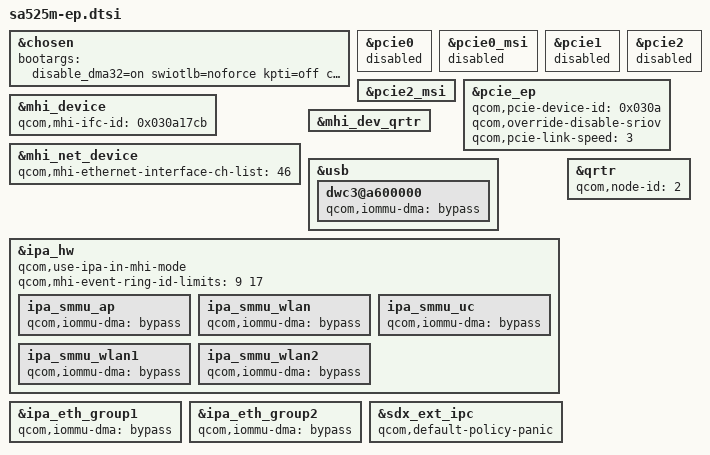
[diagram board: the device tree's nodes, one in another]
&chosen {
	bootargs = "disable_dma32=on swiotlb=noforce kpti=off cpufreq.default_governor=performance pcie_ports=compat msm_rtb.filter=0x237 ftrace_dump_on_oops reboot=w";
};

&pcie0 {
	status = "disabled";
};

&pcie0_msi {
	status = "disabled";
};

&pcie1 {
	status = "disabled";
};

&pcie2 {
	status = "disabled";
};

&pcie2_msi {
	status = "ok";
};

&pcie_ep {
	qcom,pcie-device-id = /bits/ 16 <0x030a>;
	qcom,override-disable-sriov;
	qcom,pcie-link-speed = <3>; /* Set max link speed to Gen3 */
	status = "ok";
};

&mhi_device {
	qcom,mhi-ifc-id = <0x030a17cb>;
	status = "ok";
};

&mhi_net_device {
	qcom,mhi-ethernet-interface-ch-list = <46>;
	status = "ok";
};

&mhi_dev_qrtr {
	status = "ok";
};

&usb {
	dwc3@a600000 {
		qcom,iommu-dma = "bypass";
	};
};
&ipa_hw {
	qcom,use-ipa-in-mhi-mode;
	qcom,mhi-event-ring-id-limits = <9 17>;

	ipa_smmu_ap: ipa_smmu_ap {
		qcom,iommu-dma = "bypass";
	};

	ipa_smmu_wlan: ipa_smmu_wlan {
		qcom,iommu-dma = "bypass";
	};

	ipa_smmu_uc: ipa_smmu_uc {
		qcom,iommu-dma = "bypass";
	};

	ipa_smmu_wlan1: ipa_smmu_wlan1 {
		qcom,iommu-dma = "bypass";
	};

	ipa_smmu_wlan2: ipa_smmu_wlan2 {
		qcom,iommu-dma = "bypass";
	};
};

&ipa_eth_group1 {
	qcom,iommu-dma = "bypass";
};

&ipa_eth_group2 {
	qcom,iommu-dma = "bypass";
};

&qrtr {
	qcom,node-id = <2>;
};

&sdx_ext_ipc {
	/delete-property/qcom,default-policy-nop;
	qcom,default-policy-panic;
};
